# D1H register map
Vendor: Allwinner; File version: 1.0
Registers are 32-bit, read-write, reset 0x0 unless marked. A register's access mark holds for its fields unless they carry their own. Offsets are from the block's base; [hi:lo] are bit positions; {n}, {i} and the like mark numbered series.

## DMAC — Direct Memory Access Controller
Base 0x03002000
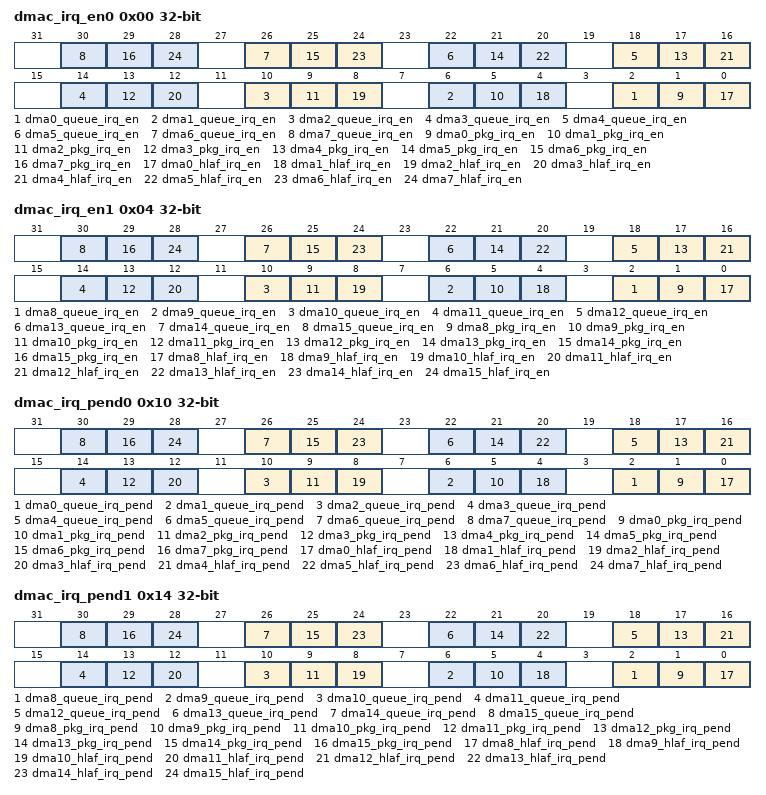
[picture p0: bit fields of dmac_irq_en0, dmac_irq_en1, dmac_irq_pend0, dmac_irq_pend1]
0x00 dmac_irq_en0 — DMAC IRQ Enable Register 0
  [all] fields
    0=DISABLED; 1=ENABLED
  [4n+2] dma{n}_queue_irq_en (n=0..7) — Enable the queue end interrupt of DMA
  [4n+1] dma{n}_pkg_irq_en (n=0..7) — Enable the package end interrupt of DMA
  [4n] dma{n}_hlaf_irq_en (n=0..7) — Enable the half package interrupt of DMA
0x04 dmac_irq_en1 — DMAC IRQ Enable Register 1
  [all] fields
    0=DISABLED; 1=ENABLED
  [4n-30] dma{n}_queue_irq_en (n=8..15) — Enable the queue end interrupt of DMA
  [4n-31] dma{n}_pkg_irq_en (n=8..15) — Enable the package end interrupt of DMA
  [4n-32] dma{n}_hlaf_irq_en (n=8..15) — Enable the half package interrupt of DMA
0x10 dmac_irq_pend0 — DMAC IRQ Pending Register 0
  [all] fields
    0=NO_EFFECT; 1=PENDING
  [4n+2] dma{n}_queue_irq_pend (n=0..7) — The IRQ pending bit for the queue end interrupt of DMA
  [4n+1] dma{n}_pkg_irq_pend (n=0..7) — The IRQ pending bit for the package end interrupt of DMA
  [4n] dma{n}_hlaf_irq_pend (n=0..7) — The IRQ pending bit for the half package interrupt of DMA
0x14 dmac_irq_pend1 — DMAC IRQ Pending Register 1
  [all] fields
    0=NO_EFFECT; 1=PENDING
  [4n-30] dma{n}_queue_irq_pend (n=8..15) — The IRQ pending bit for the queue end interrupt of DMA
  [4n-31] dma{n}_pkg_irq_pend (n=8..15) — The IRQ pending bit for the package end interrupt of DMA
  [4n-32] dma{n}_hlaf_irq_pend (n=8..15) — The IRQ pending bit for the half package interrupt of DMA
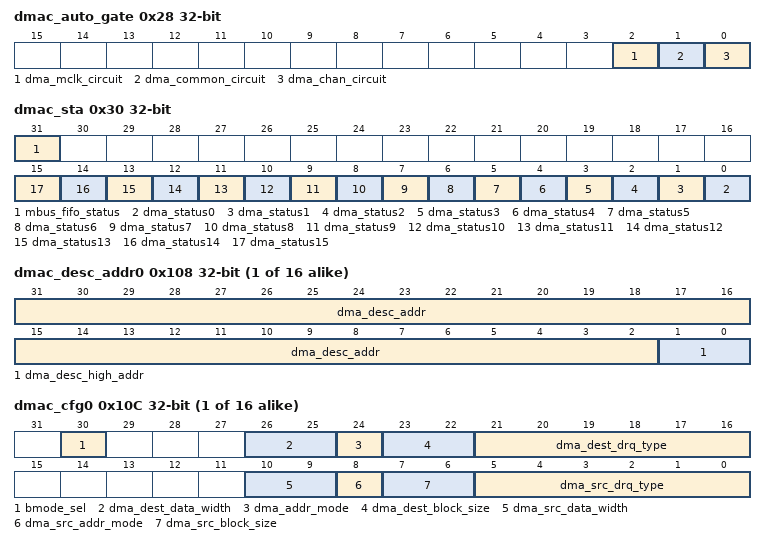
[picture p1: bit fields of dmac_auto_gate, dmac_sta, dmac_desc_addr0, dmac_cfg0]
0x28 dmac_auto_gate — DMAC Auto Gating Register
  [all] fields
    0=ENABLED; 1=DISABLED
  [2] dma_mclk_circuit — Auto gating bit of DMA MCLK interfact circuit
  [1] dma_common_circuit — Auto gating bit of DMA common circuit
  [0] dma_chan_circuit — Auto gating bit of DMA channel circuit
0x30 dmac_sta ro — DMAC Status Register
  [31] mbus_fifo_status
    0=EMPTY; 1=NOT_EMPTY
  [n] dma_status{n} (n=0..15) — DMA Channel[15:0] Status
    0=IDLE; 1=BUSY
{0x100+0x40*i} dmac_en{i} (i=0..15) — DMAC Channel Enable Register
  [0] dma_en — DMA Channel Enable
    0=DISABLED; 1=ENABLED
{0x104+0x40*i} dmac_pau{i} (i=0..15) — DMAC Channel Pause Register
  [0] dma_pause — Pause the DMA Channel Transfer Data
    0=RESUME; 1=PAUSE
{0x108+0x40*i} dmac_desc_addr{i} (i=0..15) — DMAC Channel Start Address Register
  [31:2] dma_desc_addr — Lower 30 bits of DMA channel descriptor address
  [1:0] dma_desc_high_addr — Higher 2 bits of DMA channel descriptor high address . DMA Channel Descriptor Address = {bit[1:0], bit[31:2], 2'b00}
{0x10C+0x40*i} dmac_cfg{i} (i=0..15) ro — DMAC Channel Configuration Register
  [30] bmode_sel
    0=NORMAL; 1=BMODE
  [26:25] dma_dest_data_width — DMA Destination Data Width
    0=B8 (8 bit); 1=B16 (16 bit); 2=B32 (32 bit); 3=B64 (64 bit)
  [24] dma_addr_mode — DMA Destination Address Mode
    0=LINEAR; 1=IO
  [23:22] dma_dest_block_size — DMA Destination Block Size
    0=S1; 1=S4; 2=S8; 3=S16
  [21:16] dma_dest_drq_type — DMA Destination DRQ Type
  [10:9] dma_src_data_width — DMA Source Data Width
    0=B8 (8 bit); 1=B16 (16 bit); 2=B32 (32 bit); 3=B64 (64 bit)
  [8] dma_src_addr_mode — DMA Source Address Mode
    0=LINEAR; 1=IO
  [7:6] dma_src_block_size — DMA Source Block Size
    0=S1; 1=S4; 2=S8; 3=S16
  [5:0] dma_src_drq_type — DMA Source DRQ Type
{0x110+0x40*i} dmac_cur_src{i} (i=0..15) ro — DMAC Channel Current Source Register
{0x114+0x40*i} dmac_cur_dest{i} (i=0..15) ro — DMAC Channel Current Destination Register
{0x118+0x40*i} dmac_bcnt_left{i} (i=0..15) ro — DMAC Channel Byte Counter Left Register
  [24:0] dma_bcnt_left — DMA Channel Byte Counter Left
{0x11C+0x40*i} dmac_para{i} (i=0..15) ro — DMAC Channel Parameter Register
  [7:0] wait_cyc — Wait Clock Cycle
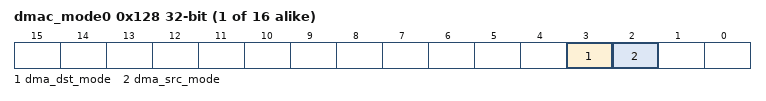
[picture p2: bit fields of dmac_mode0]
{0x128+0x40*i} dmac_mode{i} (i=0..15)
  [3] dma_dst_mode — Destination Communication Mode Select
    0=WAITING; 1=HANDSHAKE
  [2] dma_src_mode — Source Communication Mode Select
    0=WAITING; 1=HANDSHAKE
{0x12C+0x40*i} dmac_fdesc_addr{i} (i=0..15) ro — DMAC Former Descriptor Address Register
{0x130+0x40*i} dmac_pkg_num{i} (i=0..15) ro — DMAC Package Number Register
